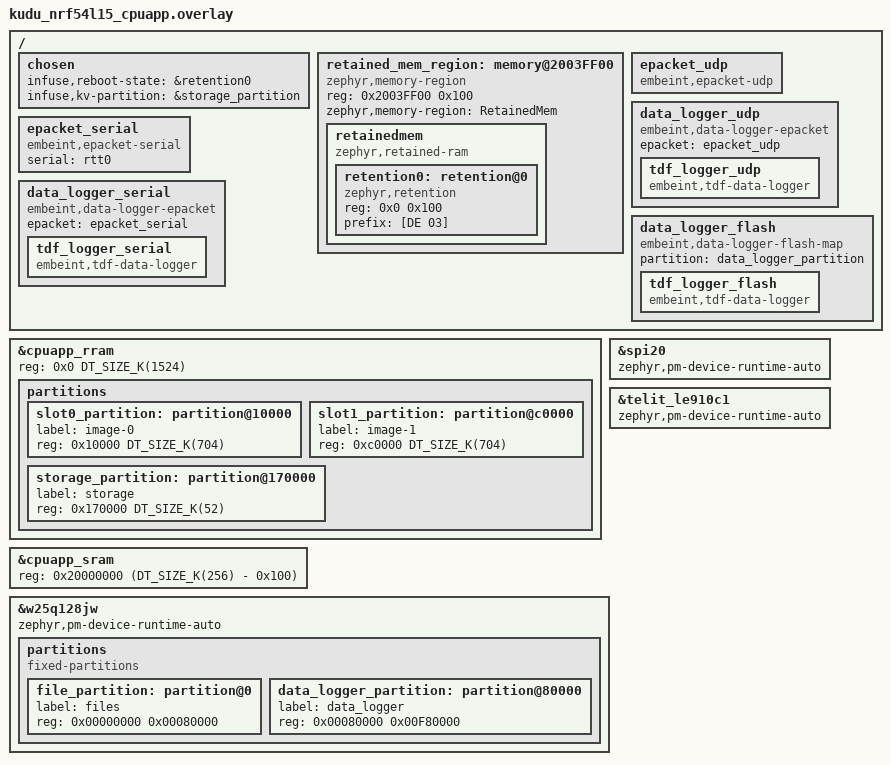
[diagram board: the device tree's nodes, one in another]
#include <common/nordic/infuse_nrf54l15_cpuapp.dtsi>
#include <common/infuse_bluetooth.dtsi>

/* Recover the FLPR core RRAM and RAM for the main application */
&cpuapp_rram {
	reg = <0x0 DT_SIZE_K(1524)>;
};
&cpuapp_sram {
	reg = <0x20000000 (DT_SIZE_K(256) - 0x100)>;
	ranges = <0x0 0x20000000 (DT_SIZE_K(256) - 0x100)>;
};
/delete-node/ &slot0_partition;
/delete-node/ &slot1_partition;
/delete-node/ &storage_partition;
/delete-node/ &retained_mem_region;

/ {
	chosen {
		infuse,reboot-state = &retention0;
		infuse,kv-partition = &storage_partition;
	};

	/* Move the retained memory region to the new end of application RAM */
	retained_mem_region: memory@2003FF00 {
		compatible = "zephyr,memory-region", "mmio-sram";
		reg = <0x2003FF00 0x100>;
		zephyr,memory-region = "RetainedMem";
		status = "okay";

		retainedmem {
			compatible = "zephyr,retained-ram";
			status = "okay";
			#address-cells = <1>;
			#size-cells = <1>;

			retention0: retention@0 {
				compatible = "zephyr,retention";
				status = "okay";
				reg = <0x0 0x100>;
				prefix = [DE 03];
			};
		};
	};

	epacket_udp: epacket_udp {
		compatible = "embeint,epacket-udp";
	};

	data_logger_udp: data_logger_udp {
		compatible = "embeint,data-logger-epacket", "embeint,data-logger";
		epacket = <&epacket_udp>;

		tdf_logger_udp: tdf_logger_udp {
			compatible = "embeint,tdf-data-logger";
		};
	};

	epacket_serial: epacket_serial {
		compatible = "embeint,epacket-serial";
		serial = <&rtt0>;
	};

	data_logger_serial: data_logger_serial {
		compatible = "embeint,data-logger-epacket", "embeint,data-logger";
		epacket = <&epacket_serial>;

		tdf_logger_serial: tdf_logger_serial {
			compatible = "embeint,tdf-data-logger";
		};
	};

	data_logger_flash: data_logger_flash {
		compatible = "embeint,data-logger-flash-map", "embeint,data-logger";
		partition = <&data_logger_partition>;

		tdf_logger_flash: tdf_logger_flash {
			compatible = "embeint,tdf-data-logger";
		};
	};
};

&spi20 {
	zephyr,pm-device-runtime-auto;
};

&telit_le910c1 {
	zephyr,pm-device-runtime-auto;
};

&cpuapp_rram {
	partitions {
		slot0_partition: partition@10000 {
			label = "image-0";
			reg = <0x10000 DT_SIZE_K(704)>;
		};
		slot1_partition: partition@c0000 {
			label = "image-1";
			reg = <0xc0000 DT_SIZE_K(704)>;
		};
		storage_partition: partition@170000 {
			label = "storage";
			reg = <0x170000 DT_SIZE_K(52)>;
		};
	};
};

&w25q128jw {
	zephyr,pm-device-runtime-auto;
	partitions {
		compatible = "fixed-partitions";
		#address-cells = <1>;
		#size-cells = <1>;

		file_partition: partition@0 {
			label = "files";
			reg = <0x00000000 0x00080000>;
		};
		data_logger_partition: partition@80000 {
			label = "data_logger";
			reg = <0x00080000 0x00F80000>;
		};
	};
};
